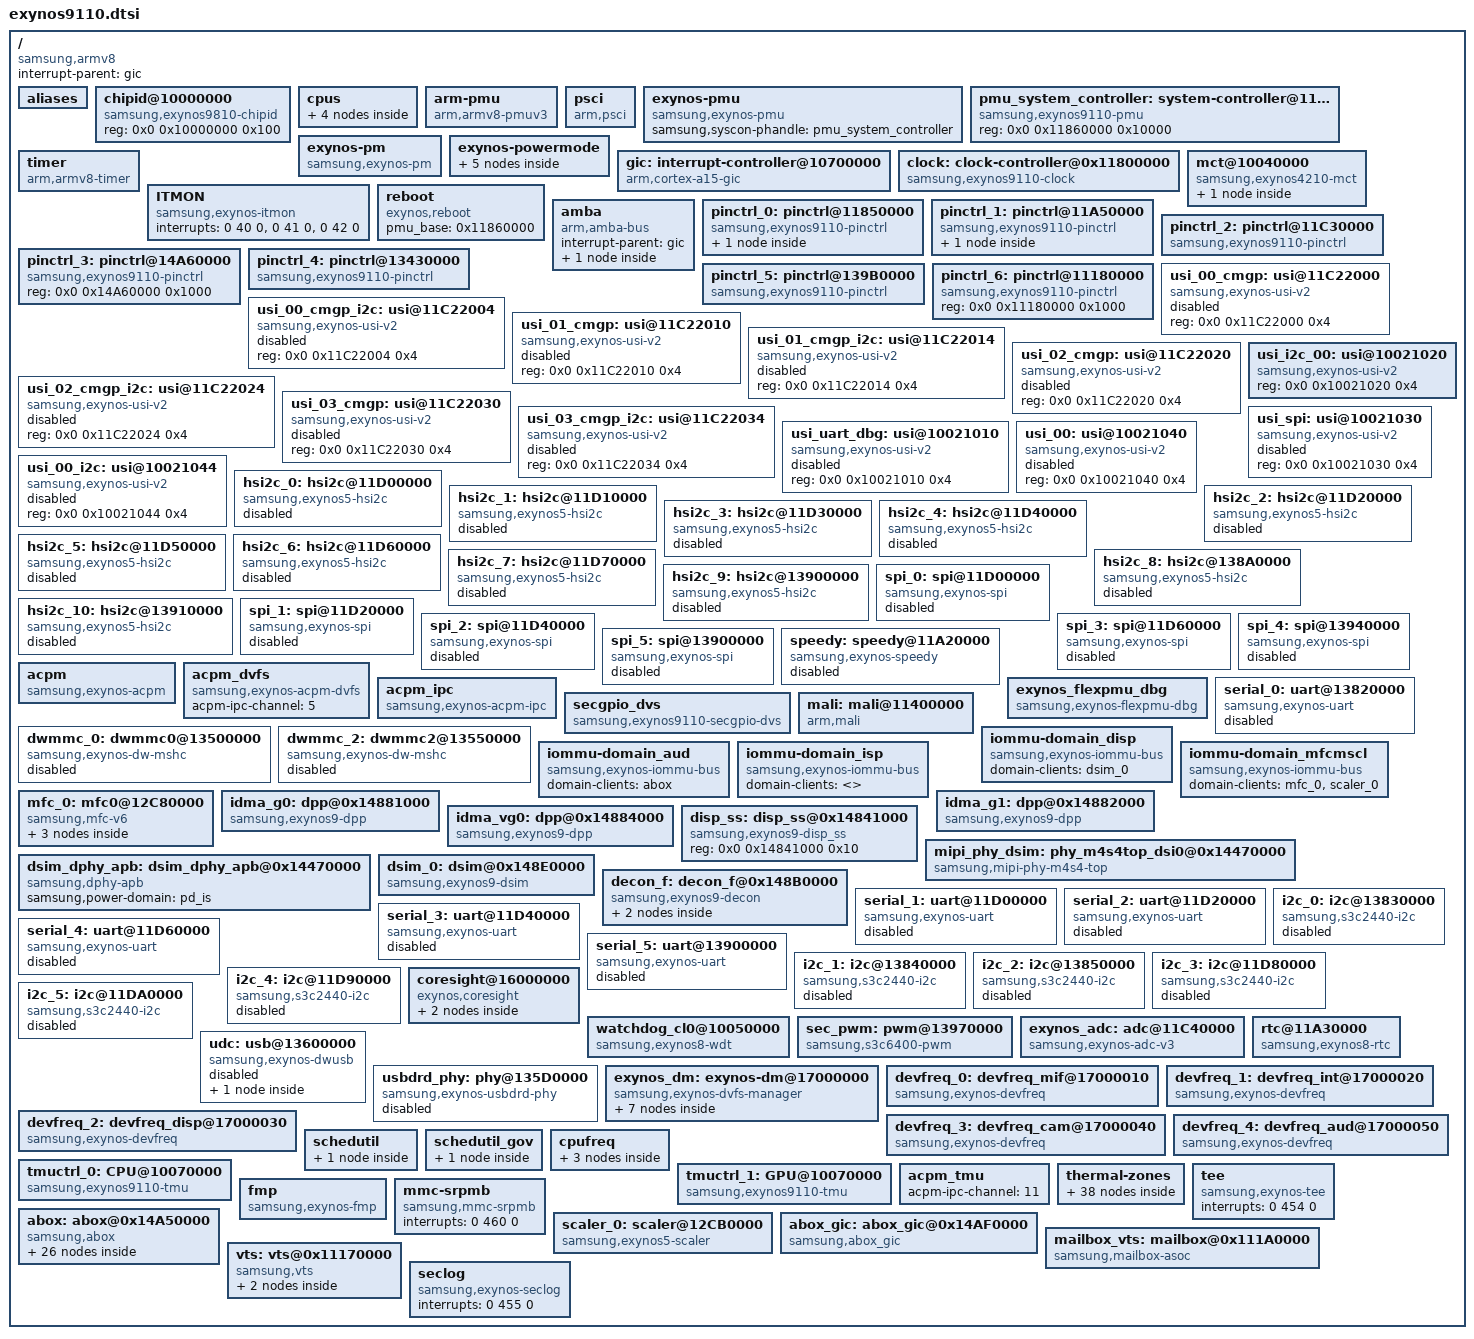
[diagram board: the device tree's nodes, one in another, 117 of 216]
/*
 * SAMSUNG EXYNOS9110 SoC device tree source
 *
 * Copyright (c) 2017 Samsung Electronics Co., Ltd.
 *		http://www.samsung.com
 *
 * SAMSUNG EXYNOS9110 SoC device nodes are listed in this file.
 * EXYNOS9110 based board files can include this file and provide
 * values for board specfic bindings.
 *
 * This program is free software; you can redistribute it and/or modify
 * it under the terms of the GNU General Public License version 2 as
 * published by the Free Software Foundation.
 */

#include <dt-bindings/clock/exynos9110.h>
#include <dt-bindings/soc/samsung/exynos9110.h>
#include <dt-bindings/interrupt-controller/arm-gic.h>
#include <dt-bindings/interrupt-controller/exynos9110.h>
#include "exynos9110-sysmmu.dtsi"
#include "exynos9110-pm-domains.dtsi"
#include "tgm-drm.dtsi"

/ {
	compatible = "samsung,armv8", "samsung,exynos9110";
	interrupt-parent = <&gic>;
	#address-cells = <2>;
	#size-cells = <1>;

	aliases {
		pinctrl0 = &pinctrl_0;
		pinctrl1 = &pinctrl_1;
		pinctrl2 = &pinctrl_2;
		pinctrl3 = &pinctrl_3;
		pinctrl4 = &pinctrl_4;
		pinctrl5 = &pinctrl_5;
		pinctrl6 = &pinctrl_6;
		mshc0 = &dwmmc_0;
		mshc2 = &dwmmc_2;
		dpp0 = &idma_g0;
		dpp1 = &idma_g1;
		dpp2 = &idma_vg0;
		dsim0 = &dsim_0;
		decon0 = &decon_f;
		usi0 = &usi_00_cmgp;
		usi1 = &usi_00_cmgp_i2c;
		usi2 = &usi_01_cmgp;
		usi3 = &usi_01_cmgp_i2c;
		usi4 = &usi_02_cmgp;
		usi5 = &usi_02_cmgp_i2c;
		usi6 = &usi_03_cmgp;
		usi7 = &usi_03_cmgp_i2c;
		usi8 = &usi_uart_dbg;
		usi9 = &usi_i2c_00;
		usi10 = &usi_spi;
		usi11 = &usi_00;
		usi12 = &usi_00_i2c;
		hsi2c0 = &hsi2c_0;
		hsi2c1 = &hsi2c_1;
		hsi2c2 = &hsi2c_2;
		hsi2c3 = &hsi2c_3;
		hsi2c4 = &hsi2c_4;
		hsi2c5 = &hsi2c_5;
		hsi2c6 = &hsi2c_6;
		hsi2c7 = &hsi2c_7;
		hsi2c8 = &hsi2c_8;
		hsi2c9 = &hsi2c_9;
		hsi2c10 = &hsi2c_10;
		spi0 = &spi_0;
		spi1 = &spi_1;
		spi2 = &spi_2;
		spi3 = &spi_3;
		spi4 = &spi_4;
		spi5 = &spi_5;
		uart0 = &serial_0;
		ecduart = &serial_0;
		uart1 = &serial_1;
		uart2 = &serial_2;
		uart3 = &serial_3;
		uart4 = &serial_4;
		uart5 = &serial_5;
		scaler0 = &scaler_0;
		mfc0 = &mfc_0;
	};

	chipid@10000000 {
		compatible = "samsung,exynos9810-chipid";
		reg = <0x0 0x10000000 0x100>;
	};

	cpus {
		#address-cells = <2>;
		#size-cells = <0>;

		cpu_l0:cpu@0 {
			device_type = "cpu";
			compatible = "arm,ananke", "arm,armv8";
			reg = <0x0 0x0>;
			enable-method = "psci";
			cpu-idle-states = <&BOOTCL_CPU_SLEEP>;
		};
		cpu_l1:cpu@1 {
			device_type = "cpu";
			compatible = "arm,ananke", "arm,armv8";
			reg = <0x0 0x1>;
			enable-method = "psci";
			cpu-idle-states = <&BOOTCL_CPU_SLEEP>;
		};
		idle-states {
			entry-method = "arm,psci";

			BOOTCL_CPU_SLEEP: bootcl-cpu-sleep {
				idle-state-name = "c2";
				compatible = "exynos,idle-state";
				arm,psci-suspend-param = <0x0010000>;
				entry-latency-us = <35>;
				exit-latency-us = <90>;
				min-residency-us = <750>;
				status = "okay";
			};
		};
	};

	arm-pmu {
		compatible = "arm,armv8-pmuv3";
		interrupts = <GIC_SPI 152 IRQ_TYPE_LEVEL_HIGH>,
			      <GIC_SPI 153 IRQ_TYPE_LEVEL_HIGH>;
		interrupt-affinity = <&cpu_l0>, <&cpu_l1>;
	};

	psci {
		compatible = "arm,psci";
		method = "smc";
		cpu_suspend = <0xC4000001>;
		cpu_off = <0x84000002>;
		cpu_on = <0xC4000003>;
	};

	exynos-pmu {
		compatible = "samsung,exynos-pmu";
		samsung,syscon-phandle = <&pmu_system_controller>;
	};

	pmu_system_controller: system-controller@11860000 {
		compatible = "samsung,exynos9110-pmu", "syscon";
		reg = <0x0 0x11860000 0x10000>;
	};

	exynos-pm {
		compatible = "samsung,exynos-pm";
		reg = <0x0 0x11850000 0x1000>,
		    <0x0 0x10701200 0x100>;
		reg-names = "gpio_alive_base",
				"gicd_ispendrn_base";
		num-eint = <13>;
		num-gic = <16>;
		suspend_mode_idx = <8>;		/* SYS_SLEEP */
		suspend_psci_idx = <133>;	/* PSCI_SYSTEM_SLEEP */
		cp_call_mode_idx = <10>;	/* SYS_SLEEP_AUD_ON */
		cp_call_psci_idx = <133>;	/* PSCI_SYSTEM_SLEEP */

		usbl2_suspend_available = <1>;	/* SYS_SLEEP_AUD_ON */
		usbl2_suspend_mode_idx = <12>;	/* SYS_SLEEP_AUD_ON */
		extra_wakeup_stat = <0x640>;
	};

	exynos-powermode {
		sicd_residency = <3000>;
		sicd_enabled = <1>;
		sicd_block_jig = <1>;

		idle-ip = "13970000.pwm",		/* [ 0] pwm		*/
			  "11c40000.adc",		/* [ 1] adc		*/
			  "11d00000.hsi2c",		/* [ 2] hsi2c_0		*/
			  "11d10000.hsi2c",		/* [ 3] hsi2c_1		*/
			  "11d20000.hsi2c",		/* [ 4] hsi2c_2		*/
			  "11d30000.hsi2c",		/* [ 5] hsi2c_3		*/
			  "11d40000.hsi2c",		/* [ 6] hsi2c_4		*/
			  "11d50000.hsi2c",		/* [ 7] hsi2c_5		*/
			  "11d60000.hsi2c",		/* [ 8] hsi2c_6		*/
			  "11d70000.hsi2c",		/* [ 9] hsi2c_7		*/
			  "138a0000.hsi2c",		/* [10] hsi2c_8		*/
			  "13900000.hsi2c",		/* [11] hsi2c_9		*/
			  "13910000.hsi2c",		/* [12] hsi2c_10	*/
			  "11d00000.spi",		/* [13] spi_0		*/
			  "11d20000.spi",		/* [14] spi_1		*/
			  "11d40000.spi",		/* [15] spi_2		*/
			  "11d60000.spi",		/* [16] spi_3		*/
			  "13940000.spi",		/* [17] spi_4		*/
			  "13900000.spi",		/* [18] spi_5		*/
			  "13500000.dwmmc0",		/* [19] dwmmc0		*/
			  "13550000.dwmmc2",		/* [20] dwmmc2		*/
			  "13600000.usb",		/* [21] usb		*/
			  "148e0000.dsim",		/* [22] dsim		*/
			  /* index for power-domain */
			  "pd-dispaud",			/* [23] pd-dispaud	*/
			  "pd-g3d",			/* [24] pd-g3d		*/
			  "pd-is",			/* [25] pd-is		*/
			  "pd-mfcmscl",			/* [26] pd-mfcmscl	*/
			  "pd-vts",			/* [27] pd-vts		*/
			  "bluetooth";			/* [28] bluetooth */

		fix-idle-ip = "acpm_dvfs";
		fix-idle-ip-index = <96>;

		idle_ip_mask {
			sicd: SYS_SICD {
				mode-index = <0>;
				ref-idle-ip = <0>,  <1>,  <2>,  <3>,  <4>,  <5>,  <6>,  <7>,  <8>,  <9>,
					     <10>, <11>, <12>, <13>, <14>, <15>, <16>, <17>, <18>, <19>,
					     <20>, <21>, <22>,       <24>,       <26>,       <28>, <96>;
			};
		};

		wakeup-masks {
			/*
			 * wakeup_mask configuration
			 *	        SICD          SICD_CPD      AFTR          STOP
			 *              LPD           LPA           ALPA          DSTOP
			 *              SLEEP         SLEEP_VTS_ON  SLEEP_AUD_ON  FAPO USB_L2
			 */
			wakeup-mask {
				mask = <0x400001E0>, <0x0>,        <0x0>,        <0x0>,
				       <0x0>,        <0x0>,        <0x0>,        <0x0>,
				       <0x500F7E7E>, <0x500F7E7E>, <0x500F7E7E>, <0x0>, <0xD00D7E7E>;
				reg-offset = <0x610>;
			};
			wakeup-mask3 {
				mask = <0x0>,	     <0x0>, 	   <0x0>, 	 <0x0>,
				       <0x0>,        <0x0>,        <0x0>,        <0x0>,
				       <0xFFFF00FF>, <0xFFFF00FF>, <0xFFFF00FF>, <0x0>, <0xFFFF00FF>;
				reg-offset = <0x618>;
			};
		};
	};

	gic:interrupt-controller@10700000 {
		compatible = "arm,cortex-a15-gic", "arm,cortex-a9-gic";
		#interrupt-cells = <3>;
		#address-cells = <0>;
		interrupt-controller;
		reg =	<0x0 0x10701000 0x1000>,
			<0x0 0x10702000 0x1000>,
			<0x0 0x10704000 0x2000>,
			<0x0 0x10706000 0x2000>;
		interrupts = <1 9 0xf04>;
	};

	timer {
		compatible = "arm,armv8-timer";
		interrupts = <GIC_PPI 13
				(GIC_CPU_MASK_SIMPLE(8) | IRQ_TYPE_LEVEL_LOW)>,
			     <GIC_PPI 14
				(GIC_CPU_MASK_SIMPLE(8) | IRQ_TYPE_LEVEL_LOW)>,
			     <GIC_PPI 11
				(GIC_CPU_MASK_SIMPLE(8) | IRQ_TYPE_LEVEL_LOW)>,
			     <GIC_PPI 10
				(GIC_CPU_MASK_SIMPLE(8) | IRQ_TYPE_LEVEL_LOW)>;
	        clock-frequency = <26000000>;
		use-clocksource-only;
		use-physical-timer;
	};

	clock: clock-controller@0x11800000 {
		compatible = "samsung,exynos9110-clock";
		reg = <0x0 0x11800000 0x8000>;
		acpm-ipc-channel = <0>;
		#clock-cells = <1>;
	};

	mct@10040000 {
		compatible = "samsung,exynos4210-mct";
		reg = <0x0 0x10040000 0x800>;
		interrupt-controller;
		#interrupt-cells = <1>;
		interrupt-parent = <&mct_map>;
		interrupts =	<0>, <1>, <2>, <3>,
				<4>, <5>, <6>, <7>,
				<8>, <9>, <10>, <11>;
		clocks = <&clock OSCCLK>, <&clock GATE_MCT>;
		clock-names = "fin_pll", "mct";
		use-clockevent-only;

		mct_map: mct-map {
			#interrupt-cells = <1>;
			#address-cells = <0>;
			#size-cells = <0>;
			interrupt-map = <0 &gic 0 233 0>,
					<1 &gic 0 234 0>,
					<2 &gic 0 235 0>,
					<3 &gic 0 236 0>,
					<4 &gic 0 237 0>,
					<5 &gic 0 238 0>,
					<6 &gic 0 239 0>,
					<7 &gic 0 240 0>,
					<8 &gic 0 241 0>,
					<9 &gic 0 242 0>,
					<10 &gic 0 243 0>,
					<11 &gic 0 244 0>;
		};
	};

	ITMON {
		compatible = "samsung,exynos-itmon";
		interrupts = <0 40 0>, /* DATA_CORE */
			     <0 41 0>, /* DATA_NRT */
			     <0 42 0>; /* PERI_CORE */
	};

	reboot {
		compatible = "exynos,reboot";
		pmu_base = <0x11860000>;
	};

	/* DMA */
	amba {
		#address-cells = <2>;
		#size-cells = <1>;
		compatible = "arm,amba-bus";
		interrupt-parent = <&gic>;
		ranges;

		pdma0: pdma0@10520000 {
			compatible = "arm,pl330", "arm,primecell";
			reg = <0x0 0x10520000 0x1000>;
			interrupts = <0 19 0>;
			clocks = <&clock GATE_PDMA_CORE>;
			clock-names = "apb_pclk";
			#dma-cells = <1>;
			#dma-channels = <4>;
			#dma-requests = <32>;
			#dma-multi-irq = <1>;
			dma-arwrapper = <0x10524400>,
					<0x10524420>,
					<0x10524440>,
					<0x10524460>;
			dma-awwrapper = <0x10524404>,
					<0x10524424>,
					<0x10524444>,
					<0x10524464>;
			dma-instwrapper = <0x10524480>;
			dma-mask-bit = <36>;
			coherent-mask-bit = <36>;
		};
	};

	/* ALIVE */
	pinctrl_0: pinctrl@11850000 {
		compatible = "samsung,exynos9110-pinctrl";
		reg = <0x0 0x11850000 0x1000>;
		interrupts = <0 74 0>, <0 75 0>, <0 76 0>, <0 77 0>,
				<0 78 0>, <0 79 0>, <0 80 0>, <0 81 0>,
				<0 82 0>, <0 83 0>, <0 84 0>, <0 85 0>,
				<0 86 0>, <0 87 0>;
		wakeup-interrupt-controller {
			compatible = "samsung,exynos7-wakeup-eint";
		};
	};

	/* CMGP_ALIVE */
	pinctrl_1: pinctrl@11A50000{
		compatible = "samsung,exynos9110-pinctrl";
		reg = <0x0 0x11A50000 0x1000>;
		interrupts = <0 122 0>, <0 123 0>, <0 124 0>, <0 125 0>,
				<0 142 0>, <0 143 0>, <0 144 0>, <0 145 0>,
				<0 146 0>, <0 147 0>;
		wakeup-interrupt-controller {
			compatible = "samsung,exynos7-wakeup-eint";
		};
	};

	/* CMGP */
	pinctrl_2: pinctrl@11C30000{
		compatible = "samsung,exynos9110-pinctrl";
		reg = <0x0 0x11C30000 0x1000>;
		interrupts = <0 126 0>, <0 127 0>, <0 128 0>, <0 129 0>,
				<0 130 0>, <0 131 0>, <0 132 0>, <0 133 0>,
				<0 134 0>, <0 135 0>, <0 136 0>, <0 137 0>,
				<0 138 0>, <0 139 0>, <0 140 0>, <0 141 0>;
	};

	/* DISPAUD */
	pinctrl_3: pinctrl@14A60000{
		compatible = "samsung,exynos9110-pinctrl";
		reg = <0x0 0x14A60000 0x1000>;
	};

	/* FSYS */
	pinctrl_4: pinctrl@13430000 {
		compatible = "samsung,exynos9110-pinctrl";
		reg = <0x0 0x13430000 0x1000>;
		interrupts = <0 180 0>;
	};

	/* PERI */
	pinctrl_5: pinctrl@139B0000 {
		compatible = "samsung,exynos9110-pinctrl";
		reg = <0x0 0x139B0000 0x1000>;
		interrupts = <0 256 0>;
	};

	/* VTS */
	pinctrl_6: pinctrl@11180000{
		compatible = "samsung,exynos9110-pinctrl";
		reg = <0x0 0x11180000 0x1000>;
	};

	/* USI_00_CMGP */
	usi_00_cmgp: usi@11C22000 {
		compatible = "samsung,exynos-usi-v2";
		reg = <0x0 0x11C22000 0x4>;
		/*	usi_mode_v2 = "i2c" or "spi" or "uart"	*/
		status = "disabled";
	};

	/* USI_00_CMGP_I2C */
	usi_00_cmgp_i2c: usi@11C22004 {
		compatible = "samsung,exynos-usi-v2";
		reg = <0x0 0x11C22004 0x4>;
		/*	usi_mode_v2 = "i2c" */
		status = "disabled";
	};

	/* USI_01_CMGP */
	usi_01_cmgp: usi@11C22010 {
		compatible = "samsung,exynos-usi-v2";
		reg = <0x0 0x11C22010 0x4>;
		/*	usi_mode_v2 = "i2c" or "spi" or "uart"	*/
		status = "disabled";
	};

	/* USI_01_CMGP_I2C */
	usi_01_cmgp_i2c: usi@11C22014 {
		compatible = "samsung,exynos-usi-v2";
		reg = <0x0 0x11C22014 0x4>;
		/*	usi_mode_v2 = "i2c" */
		status = "disabled";
	};

	/* USI_02_CMGP */
	usi_02_cmgp: usi@11C22020 {
		compatible = "samsung,exynos-usi-v2";
		reg = <0x0 0x11C22020 0x4>;
		/*	usi_mode_v2 = "i2c" or "spi" or "uart"	*/
		status = "disabled";
	};

	/* USI_02_CMGP_I2C */
	usi_02_cmgp_i2c: usi@11C22024 {
		compatible = "samsung,exynos-usi-v2";
		reg = <0x0 0x11C22024 0x4>;
		/*	usi_mode_v2 = "i2c" */
		status = "disabled";
	};

	/* USI_03_CMGP */
	usi_03_cmgp: usi@11C22030 {
		compatible = "samsung,exynos-usi-v2";
		reg = <0x0 0x11C22030 0x4>;
		/*	usi_mode_v2 = "i2c" or "spi" or "uart"	*/
		status = "disabled";
	};

	/* USI_03_CMGP_I2C */
	usi_03_cmgp_i2c: usi@11C22034 {
		compatible = "samsung,exynos-usi-v2";
		reg = <0x0 0x11C22034 0x4>;
		/*	usi_mode_v2 = "i2c" */
		status = "disabled";
	};

	/* USI_UART_DBG */
	usi_uart_dbg: usi@10021010 {
		compatible = "samsung,exynos-usi-v2";
		reg = <0x0 0x10021010 0x4>;
		/*	usi_mode_v2 = "i2c" */
		status = "disabled";
	};

	/* USI_I2C_00 */
	usi_i2c_00: usi@10021020 {
		compatible = "samsung,exynos-usi-v2";
		reg = <0x0 0x10021020 0x4>;
		/*	usi_mode_v2 = "i2c" */
		status = "okay";
	};

	/* USI_SPI */
	usi_spi: usi@10021030 {
		compatible = "samsung,exynos-usi-v2";
		reg = <0x0 0x10021030 0x4>;
		/*	usi_mode_v2 = "i2c" */
		status = "disabled";
	};

	/* USI_00 */
	usi_00: usi@10021040 {
		compatible = "samsung,exynos-usi-v2";
		reg = <0x0 0x10021040 0x4>;
		/*	usi_mode_v2 = "i2c" */
		status = "disabled";
	};

	/* USI_00_I2C */
	usi_00_i2c: usi@10021044 {
		compatible = "samsung,exynos-usi-v2";
		reg = <0x0 0x10021044 0x4>;
		/*	usi_mode_v2 = "i2c" */
		status = "disabled";
	};

	/* USI_00_CMGP */
	hsi2c_0: hsi2c@11D00000 {
		compatible = "samsung,exynos5-hsi2c";
		samsung,check-transdone-int;
		default-clk = <200000000>;
		reg = <0x0 0x11D00000 0x1000>;
		interrupts = <0 INTREQ_USI_CMGP_00 0>;
		#address-cells = <1>;
		#size-cells = <0>;
		pinctrl-names = "default";
		pinctrl-0 = <&hsi2c0_bus>;
		clocks = <&clock CMGP_USI0>, <&clock GATE_USI_CMGP0>;
		clock-names = "rate_hsi2c", "gate_hsi2c";
		samsung,scl-clk-stretching;
		samsung,usi-i2c-v2;
		gpio_scl= <&gpm0 0 0x1>;
		gpio_sda= <&gpm1 0 0x1>;
		status = "disabled";
	};

	/* USI_00_CMGP_I2C */
	hsi2c_1: hsi2c@11D10000 {
		compatible = "samsung,exynos5-hsi2c";
		samsung,check-transdone-int;
		default-clk = <200000000>;
		reg = <0x0 0x11D10000 0x1000>;
		interrupts = <0 INTREQ_USI_CMGP_00_I2C 0>;
		#address-cells = <1>;
		#size-cells = <0>;
		pinctrl-names = "default";
		pinctrl-0 = <&hsi2c1_bus>;
		clocks = <&clock CMGP_I2C0>, <&clock GATE_I2C_CMGP0>;
		clock-names = "rate_hsi2c", "gate_hsi2c";
		samsung,scl-clk-stretching;
		samsung,usi-i2c-v2;
		gpio_scl= <&gpm2 0 0x1>;
		gpio_sda= <&gpm3 0 0x1>;
		status = "disabled";
	};

	/* USI_01_CMGP */
	hsi2c_2: hsi2c@11D20000 {
		compatible = "samsung,exynos5-hsi2c";
		samsung,check-transdone-int;
		default-clk = <200000000>;
		reg = <0x0 0x11D20000 0x1000>;
		interrupts = <0 INTREQ_USI_CMGP_01 0>;
		#address-cells = <1>;
		#size-cells = <0>;
		pinctrl-names = "default";
		pinctrl-0 = <&hsi2c2_bus>;
		clocks = <&clock CMGP_USI1>, <&clock GATE_USI_CMGP1>;
		clock-names = "rate_hsi2c", "gate_hsi2c";
		samsung,scl-clk-stretching;
		samsung,usi-i2c-v2;
		gpio_scl= <&gpm4 0 0x1>;
		gpio_sda= <&gpm5 0 0x1>;
		status = "disabled";
	};

	/* USI_01_CMGP_I2C */
	hsi2c_3: hsi2c@11D30000 {
		compatible = "samsung,exynos5-hsi2c";
		samsung,check-transdone-int;
		default-clk = <200000000>;
		reg = <0x0 0x11D30000 0x1000>;
		interrupts = <0 INTREQ_USI_CMGP_01_I2C 0>;
		#address-cells = <1>;
		#size-cells = <0>;
		pinctrl-names = "default";
		pinctrl-0 = <&hsi2c3_bus>;
		clocks = <&clock CMGP_I2C1>, <&clock GATE_I2C_CMGP1>;
		clock-names = "rate_hsi2c", "gate_hsi2c";
		samsung,scl-clk-stretching;
		samsung,usi-i2c-v2;
		gpio_scl= <&gpm6 0 0x1>;
		gpio_sda= <&gpm7 0 0x1>;
		status = "disabled";
	};

	/* USI_02_CMGP */
	hsi2c_4: hsi2c@11D40000 {
		compatible = "samsung,exynos5-hsi2c";
		samsung,check-transdone-int;
		default-clk = <200000000>;
		reg = <0x0 0x11D40000 0x1000>;
		interrupts = <0 INTREQ_USI_CMGP_02 0>;
		#address-cells = <1>;
		#size-cells = <0>;
		pinctrl-names = "default";
		pinctrl-0 = <&hsi2c4_bus>;
		clocks = <&clock CMGP_USI2>, <&clock GATE_USI_CMGP2>;
		clock-names = "rate_hsi2c", "gate_hsi2c";
		samsung,scl-clk-stretching;
		samsung,usi-i2c-v2;
		gpio_scl= <&gpm8 0 0x1>;
		gpio_sda= <&gpm9 0 0x1>;
		status = "disabled";
	};

	/* USI_02_CMGP_I2C */
	hsi2c_5: hsi2c@11D50000 {
		compatible = "samsung,exynos5-hsi2c";
		samsung,check-transdone-int;
		default-clk = <200000000>;
		reg = <0x0 0x11D50000 0x1000>;
		interrupts = <0 INTREQ_USI_CMGP_02_I2C 0>;
		#address-cells = <1>;
		#size-cells = <0>;
		pinctrl-names = "default";
		pinctrl-0 = <&hsi2c5_bus>;
		clocks = <&clock CMGP_I2C2>, <&clock GATE_I2C_CMGP2>;
		clock-names = "rate_hsi2c", "gate_hsi2c";
		samsung,scl-clk-stretching;
		samsung,usi-i2c-v2;
		gpio_scl= <&gpm10 0 0x1>;
		gpio_sda= <&gpm11 0 0x1>;
		status = "disabled";
	};

	/* USI_03_CMGP */
	hsi2c_6: hsi2c@11D60000 {
		compatible = "samsung,exynos5-hsi2c";
		samsung,check-transdone-int;
		default-clk = <200000000>;
		reg = <0x0 0x11D60000 0x1000>;
		interrupts = <0 INTREQ_USI_CMGP_03 0>;
		#address-cells = <1>;
		#size-cells = <0>;
		pinctrl-names = "default";
		pinctrl-0 = <&hsi2c6_bus>;
		clocks = <&clock CMGP_USI3>, <&clock GATE_USI_CMGP3>;
		clock-names = "rate_hsi2c", "gate_hsi2c";
		samsung,scl-clk-stretching;
		samsung,usi-i2c-v2;
		gpio_scl= <&gpm12 0 0x1>;
		gpio_sda= <&gpm13 1 0x1>;
		status = "disabled";
	};

	/* USI_03_CMGP_I2C */
	hsi2c_7: hsi2c@11D70000 {
		compatible = "samsung,exynos5-hsi2c";
		samsung,check-transdone-int;
		default-clk = <200000000>;
		reg = <0x0 0x11D70000 0x1000>;
		interrupts = <0 INTREQ_USI_CMGP_03_I2C 0>;
		#address-cells = <1>;
		#size-cells = <0>;
		pinctrl-names = "default";
		pinctrl-0 = <&hsi2c7_bus>;
		clocks = <&clock CMGP_I2C3>, <&clock GATE_I2C_CMGP3>;
		clock-names = "rate_hsi2c", "gate_hsi2c";
		samsung,scl-clk-stretching;
		samsung,usi-i2c-v2;
		gpio_scl= <&gpm14 0 0x1>;
		gpio_sda= <&gpm15 1 0x1>;
		status = "disabled";
	};

	/* USI_I2C_00 */
	hsi2c_8: hsi2c@138A0000 {
		compatible = "samsung,exynos5-hsi2c";
		samsung,check-transdone-int;
		default-clk = <200000000>;
		reg = <0x0 0x138A0000 0x1000>;
		interrupts = <0 INTREQ_USI_I2C_00 0>;
		#address-cells = <1>;
		#size-cells = <0>;
		pinctrl-names = "default";
		pinctrl-0 = <&hsi2c8_bus>;
		clocks = <&clock PERI_HSI2C>, <&clock GATE_USI_I2C_0>;
		clock-names = "rate_hsi2c", "gate_hsi2c";
		samsung,scl-clk-stretching;
		samsung,usi-i2c-v2;
		gpio_scl= <&gpp3 0 0x1>;
		gpio_sda= <&gpp3 1 0x1>;
		status = "disabled";
	};

	/* USI_00 */
	hsi2c_9: hsi2c@13900000 {
		compatible = "samsung,exynos5-hsi2c";
		samsung,check-transdone-int;
		default-clk = <200000000>;
		reg = <0x0 0x13900000 0x1000>;
		interrupts = <0 INTREQ_USI_00 0>;
		#address-cells = <1>;
		#size-cells = <0>;
		pinctrl-names = "default";
		pinctrl-0 = <&hsi2c9_bus>;
		clocks = <&clock PERI_BUS>, <&clock GATE_I2C_0>;
		clock-names = "rate_hsi2c", "gate_hsi2c";
		samsung,scl-clk-stretching;
		samsung,usi-i2c-v2;
		gpio_scl= <&gpc0 0 0x1>;
		gpio_sda= <&gpc0 1 0x1>;
		status = "disabled";
	};

	/* USI_00_I2C */
	hsi2c_10: hsi2c@13910000 {
		compatible = "samsung,exynos5-hsi2c";
		samsung,check-transdone-int;
		default-clk = <200000000>;
		reg = <0x0 0x13910000 0x1000>;
		interrupts = <0 INTREQ_USI_00_I2C 0>;
		#address-cells = <1>;
		#size-cells = <0>;
		pinctrl-names = "default";
		pinctrl-0 = <&hsi2c10_bus>;
		clocks = <&clock PERI_BUS>, <&clock GATE_I2C_1>;
		clock-names = "rate_hsi2c", "gate_hsi2c";
		samsung,scl-clk-stretching;
		samsung,usi-i2c-v2;
		gpio_scl= <&gpc0 2 0x1>;
		gpio_sda= <&gpc0 3 0x1>;
		status = "disabled";
	};

	/* SPI USI_00_CMGP */
	spi_0: spi@11D00000 {
		compatible = "samsung,exynos-spi";
		reg = <0x0 0x11D00000 0x100>;
		samsung,spi-fifosize = <64>;
		interrupts = <0 INTREQ_USI_CMGP_00 0>;
/*
		dma-mode;
		dmas = <&pdma0 25 &pdma0 24>;
*/
		dma-names = "tx", "rx";
		swap-mode;
		#address-cells = <1>;
		#size-cells = <0>;
		clocks = <&clock GATE_USI_CMGP0>, <&clock CMGP_USI0>;
		clock-names = "spi", "spi_busclk0";
		pinctrl-names = "default";
		pinctrl-0 = <&spi0_bus>;
		status = "disabled";
	};

	/* SPI USI_01_CMGP */
	spi_1: spi@11D20000 {
		compatible = "samsung,exynos-spi";
		reg = <0x0 0x11D20000 0x100>;
		samsung,spi-fifosize = <64>;
		interrupts = <0 INTREQ_USI_CMGP_01 0>;
/*
		dma-mode;
		dmas = <&pdma0 25 &pdma0 24>;
*/
		dma-names = "tx", "rx";
		swap-mode;
		#address-cells = <1>;
		#size-cells = <0>;
		clocks = <&clock GATE_USI_CMGP1>, <&clock CMGP_USI1>;
		clock-names = "spi", "spi_busclk0";
		pinctrl-names = "default";
		pinctrl-0 = <&spi1_bus>;
		status = "disabled";
	};

	/* SPI USI_02_CMGP */
	spi_2: spi@11D40000 {
		compatible = "samsung,exynos-spi";
		reg = <0x0 0x11D40000 0x100>;
		samsung,spi-fifosize = <64>;
		interrupts = <0 INTREQ_USI_CMGP_02 0>;
/*
		dma-mode;
		dmas = <&pdma0 25 &pdma0 24>;
*/
		dma-names = "tx", "rx";
		swap-mode;
		#address-cells = <1>;
		#size-cells = <0>;
		clocks = <&clock GATE_USI_CMGP2>, <&clock CMGP_USI2>;
		clock-names = "spi", "spi_busclk0";
		pinctrl-names = "default";
		pinctrl-0 = <&spi2_bus>;
		status = "disabled";
	};

	/* SPI USI_03_CMGP */
	spi_3: spi@11D60000 {
		compatible = "samsung,exynos-spi";
		reg = <0x0 0x11D60000 0x100>;
		samsung,spi-fifosize = <64>;
		interrupts = <0 INTREQ_USI_CMGP_03 0>;
/*
		dma-mode;
		dmas = <&pdma0 25 &pdma0 24>;
*/
		dma-names = "tx", "rx";
		swap-mode;
		#address-cells = <1>;
		#size-cells = <0>;
		clocks = <&clock GATE_USI_CMGP3>, <&clock CMGP_USI3>;
		clock-names = "spi", "spi_busclk0";
		pinctrl-names = "default";
		pinctrl-0 = <&spi3_bus>;
		status = "disabled";
	};

	/* SPI USI_SPI */
	spi_4: spi@13940000 {
		compatible = "samsung,exynos-spi";
		reg = <0x0 0x13940000 0x100>;
		samsung,spi-fifosize = <64>;
		interrupts = <0 INTREQ_USI_SPI 0>;
/*
		dma-mode;
		dmas = <&pdma0 25 &pdma0 24>;
*/
		dma-names = "tx", "rx";
		swap-mode;
		#address-cells = <1>;
		#size-cells = <0>;
		clocks = <&clock GATE_USI_SPI>, <&clock PERI_SPI>;
		clock-names = "spi", "spi_busclk0";
		pinctrl-names = "default";
		pinctrl-0 = <&spi4_bus>;
		status = "disabled";
	};

	/* SPI USI_00 */
	spi_5: spi@13900000 {
		compatible = "samsung,exynos-spi";
		reg = <0x0 0x13900000 0x100>;
		samsung,spi-fifosize = <256>;
		interrupts = <0 INTREQ_USI_00 0>;
/*
		dma-mode;
		dmas = <&pdma0 25 &pdma0 24>;
*/
		dma-names = "tx", "rx";
		swap-mode;
		#address-cells = <1>;
		#size-cells = <0>;
		clocks = <&clock GATE_USI00_USI>, <&clock PERI_USI00_USI>;
		clock-names = "spi", "spi_busclk0";
		pinctrl-names = "default";
		pinctrl-0 = <&spi5_bus>;
		status = "disabled";
	};

	/* USI_UART DBG*/
	speedy: speedy@11A20000 {
		compatible = "samsung,exynos-speedy";
		reg = <0x0 0x11A20000 0x2000>;
		interrupts = <0 98 0>;
		#address-cells = <1>;
		#size-cells = <0>;
		pinctrl-names = "default";
		pinctrl-0 = <&speedy_bus>;
#if 0
		clocks = <&clock GATE_SPEEDY_BATCHER_WRAP_BATCHER_AP>;
		clock-names = "gate_speedy";
#endif
		status = "disabled";
	};

	acpm {
		compatible = "samsung,exynos-acpm";
		#address-cells = <2>;
		#size-cells = <1>;
		acpm-ipc-channel = <4>;
		fvmap_offset = <0x6000>;
		reg = <0x0 0x11830000 0x1000>;		/* TIMER_APM */
		reg-names = "timer_apm";
		peritimer-cnt = <0xFFFF>;
	};

	acpm_dvfs {
		compatible = "samsung,exynos-acpm-dvfs";
		acpm-ipc-channel = <5>;
	};

	acpm_ipc {
		compatible = "samsung,exynos-acpm-ipc";
		#address-cells = <2>;
		#size-cells = <1>;
		interrupts = <0 106 0>;	/* AP2APM MAILBOX SPI NUM*/
		reg = <0x0 0x11900000 0x1000>,		/* AP2APM MAILBOX */
			<0x0 0x2039000 0x30000>;	/* APM SRAM */
		initdata-base = <0x6F00>;
		num-timestamps = <32>;
		debug-log-level = <0>;
		logging-period = <500>;
		dump-base = <0x203C000>;
		dump-size = <0x17000>;			/* 92KB */
	};

	exynos_flexpmu_dbg {
		compatible = "samsung,exynos-flexpmu-dbg";
		#address-cells = <2>;
		#size-cells = <1>;
		data-base = <0x204A000>;
		data-size = <0x400>;
	};

	serial_0: uart@13820000 {
		compatible = "samsung,exynos-uart";
		samsung,separate-uart-clk;
		reg = <0x0 0x13820000 0x100>;
		samsung,fifo-size = <256>;
		interrupts = <0 INTREQ_USI_UART 0>;
		pinctrl-names = "default";
		pinctrl-0 = <&uart0_bus_single>; /* or _bus_dual */
		samsung,usi-serial-v2;
		clocks = <&clock GATE_USI_UART>, <&clock PERI_UART>;
		clock-names = "gate_pclk0", "gate_uart0";
		status = "disabled";
	};

	secgpio_dvs {
		compatible = "samsung,exynos9110-secgpio-dvs";
		status = "okay";
	};

	dwmmc_0: dwmmc0@13500000 {
		compatible = "samsung,exynos-dw-mshc";
		reg = <0x0 0x13500000 0x2000>,
			<0x0 0x13508000 0x200>;
		reg-names = "dw_mmc",
			"cmdq_mem";
		interrupts = <0 176 0>;
		#address-cells = <1>;
		#size-cells = <0>;
		clocks = <&clock FSYS_MMC_EMBD>, <&clock GATE_MMC_EMBD>;
		clock-names = "ciu", "ciu_gate";
		status = "disabled";
		fmp-id = <0>;
		smu-id = <0>;
	};

	dwmmc_2: dwmmc2@13550000 {
		compatible = "samsung,exynos-dw-mshc";
		reg = <0x0 0x13550000 0x2000>;
		reg-names = "dw_mmc";
		interrupts = <0 177 0>;
		#address-cells = <1>;
		#size-cells = <0>;
		clocks = <&clock FSYS_MMC_CARD>, <&clock GATE_MMC_CARD>;
		clock-names = "ciu", "ciu_gate";
		status = "disabled";
	 };

	mali: mali@11400000 {
		compatible = "arm,mali";
		reg = <0x0 0x11400000 0x5000>;
		interrupts = <0 70 0>, <0 71 0>, <0 69 0>;
		interrupt-names = "JOB", "MMU", "GPU";
		g3d_cmu_cal_id = <ACPM_DVFS_G3D>;
		samsung,power-domain = <&pd_g3d>;
		#cooling-cells = <2>; /* min followed by max */
	};

	iommu-domain_disp {
		compatible = "samsung,exynos-iommu-bus";
		#address-cells = <2>;
		#size-cells = <1>;
		ranges;

		domain-clients = <&dsim_0>;
	};
	iommu-domain_aud {
		compatible = "samsung,exynos-iommu-bus";
		#address-cells = <2>;
		#size-cells = <1>;
		ranges;

		domain-clients = <&abox>;
	};
	iommu-domain_isp {
		compatible = "samsung,exynos-iommu-bus";
		#address-cells = <2>;
		#size-cells = <1>;
		ranges;

		domain-clients = <>;
	};
	iommu-domain_mfcmscl {
		compatible = "samsung,exynos-iommu-bus";
		#address-cells = <2>;
		#size-cells = <1>;
		ranges;

		domain-clients = <&mfc_0>, <&scaler_0>;
	};

	mfc_0: mfc0@12C80000 {
		compatible = "samsung,mfc-v6";
		reg = <0x0 0x12C80000 0x10000>;
		interrupts = <0 206 0>;
		clock-names = "aclk_mfc";
		clocks = <&clock GATE_MFC>;
		samsung,power-domain = <&pd_mfcmscl>;
		iommus = <&sysmmu_mfcmscl>;
		status = "ok";
		ip_ver = <19>;
		clock_rate = <400000>;
		min_rate = <50000>;
		num_qos_steps = <2>;
		max_qos_steps = <2>;
		max_mb = <244800>;
		mfc_qos_table {
			mfc_qos_variant_0 {
				thrd_mb = <0>;
				freq_mfc = <267000>;
				freq_int = <200000>;
				freq_mif = <421000>;
				freq_cpu = <0>;
				freq_kfc = <0>;
				mo_value = <0>;
				time_fw = <322>;
			};
			mfc_qos_variant_1 {
				thrd_mb = <110727>;
				freq_mfc = <400000>;
				freq_int = <533000>;
				freq_mif = <1352000>;
				freq_cpu = <0>;
				freq_kfc = <0>;
				mo_value = <0>;
				time_fw = <156>;
			};
		};
	};

	idma_g0: dpp@0x14881000 {
		compatible = "samsung,exynos9-dpp";
		#pb-id-cells = <3>;
		/* DPP(fake), DPU_DMA, DPU_DMA_COMMON */
		reg = <0x0 0x14891000 0x1000>, <0x0 0x14881000 0x1000>, <0x0 0x14880000 0x110>;
		/* DPU_DMA IRQ, DPP IRQ */
		/* 54, 58 */
		interrupts = <0 54 0>, <0 58 0>;
/*		interrupts = <0 INTREQ__DPU_DMA_G0 0>, <0 INTREQ__DPU_DPP_G0 0>; */
	};

	idma_g1: dpp@0x14882000 {
		compatible = "samsung,exynos9-dpp";
		#pb-id-cells = <3>;
		/* DPP(fake), DPU_DMA */
		reg = <0x0 0x14892000 0x1000>, <0x0 0x14882000 0x1000>;
		/* DPU_DMA IRQ, DPP IRQ */
		/* 55, 59 */
		interrupts = <0 55 0>, <0 59 0>;
/*		interrupts = <0 INTREQ__DPU_DMA_G1 0>, <0 INTREQ__DPU_DPP_G1 0>; */
	};

	idma_vg0: dpp@0x14884000 {
		compatible = "samsung,exynos9-dpp";
		#pb-id-cells = <3>;
		/* DPP, DPU_DMA */
		reg = <0x0 0x14894000 0x1000>, <0x0 0x14884000 0x1000>;
		/* DPU_DMA IRQ, DPP IRQ */
		/* 57, 61 */
		interrupts = <0 57 0>, <0 61 0>;
/*		interrupts = <0 INTREQ__DPU_DMA_VG 0>, <0 INTREQ__DPU_DPP_VG 0>; */
	};

	disp_ss: disp_ss@0x14841000 {
		compatible = "samsung,exynos9-disp_ss";
		/* MIPI PHY CON : 0x14841008 */
		reg = <0x0 0x14841000 0x10>;
	};

	mipi_phy_dsim: phy_m4s4top_dsi0@0x14470000 {
		compatible = "samsung,mipi-phy-m4s4-top";
		samsung,pmu-syscon = <&pmu_system_controller>;
		/* MIPI_PHY_M4S4S2_TOP_CONTROL : PMU_BASE + 0x0730 */
		isolation = <0x0730>;
		/* PHY reset be controlled from DSIM */
		/* reg = <0x0 0x12821008 0x4>; */
		/* reset = <0 1>; */
		/* init = <4 5>; */ /* PHY reset control path bit of SYSREG */
		owner = <0>; /* 0: DSI,  1: CSI */
		#phy-cells = <1>;
	};

	dsim_dphy_apb: dsim_dphy_apb@0x14470000 {
		compatible = "samsung,dphy-apb";
		samsung,power-domain = <&pd_is>;
	};

	dsim_0: dsim@0x148E0000 {
		compatible = "samsung,exynos9-dsim";
		/* DSIM0, DPHY M4S4(APB) */
		reg = <0x0 0x148E0000 0x100>, <0x0 0x14470000 0x4000>;
		/* 53 */
		interrupts = <0 53 0>;
/*		interrupts = <0 INTREQ__DSIM0 0>; */
		iommus = <&sysmmu_dpu>;

		/* clock */
		clock-names = "aclk";
		clocks = <&clock GATE_DPU_S_DECON>;

		phys = <&mipi_phy_dsim 0>;
		phy-names = "dsim_dphy";

		/* power domain */
		samsung,power-domain = <&pd_dispaud>;
	};

	decon_f: decon_f@0x148B0000 {
		compatible = "samsung,exynos9-decon"; /* exynos9810 */
		#pb-id-cells = <4>;
		reg = <0x0 0x148B0000 0x10000>;

		/* interrupt num : FRAME_START, FRMAE_DONE, EXTRA, GPIO_PERIC1(EXT_INT_TE: GPC1[0]) */
		/* 50, 51, 52, 256 */
		interrupts = <0 50 0>,
			     <0 51 0>,
			     <0 52 0>,
			     <0 256 0>;
/*
		interrupts = <0 INTREQ__DPU_DECON0_FRAME_START 0>,
			     <0 INTREQ__DPU_DECON0_FRAME_DONE 0>,
			     <0 INTREQ__DPU_DECON0_EXTRA 0>,
			     <0 INTREQ__GPIO_PERIC 0>;
*/
		/* pinctrl */
		pinctrl-names = "hw_te_on", "hw_te_off";
		pinctrl-0 = <&decon_f_te_on &disp_rst_prev>;
		pinctrl-1 = <&decon_f_te_off &disp_rst_in>;

		max_win = <3>;
		default_win = <0>;
		default_idma = <0>;
		psr_mode = <2>;         /* 0: video mode, 1: DP command mode, 2: MIPI command mode */
		trig_mode = <0>;        /* 0: hw trigger, 1: sw trigger */
		dsi_mode = <0>;         /* 0: single dsi, 1: dual dsi */

		/* 0: DSI, 1: eDP, 2:HDMI, 3: WB */
		out_type = <0>;
		/* 0: DSI0, 1: DSI1, 2: DSI2 */
		out_idx = <0>;

		#address-cells = <2>;
		#size-cells = <1>;
		ranges;

		/* EINT for TE */
		gpios = <&gpc1 0 0xf>;
		/* sw te pending register */
		te_eint {
			/* NWEINT_GPC1_PEND */
			reg = <0x0 0x139B0A18 0x4>;
		};

		cam-stat {
			/* IS_STATUS */
			reg = <0x0 0x11864014 0x4>;
		};
	};

	/* USI_00_CMGP */
	serial_1: uart@11D00000 {
		compatible = "samsung,exynos-uart";
		samsung,separate-uart-clk;
		reg = <0x0 0x11D00000 0x100>;
		samsung,fifo-size = <64>;
		interrupts = <0 INTREQ_USI_CMGP_00 0>;
		pinctrl-names = "default";
		pinctrl-0 = <&uart1_bus_single>; /* or _bus_dual */
		samsung,usi-serial-v2;
		clocks = <&clock GATE_USI_CMGP0>, <&clock CMGP_USI0>;
		clock-names = "gate_pclk1", "gate_uart1";
		status = "disabled";
	};

	/* USI_01_CMGP */
	serial_2: uart@11D20000 {
		compatible = "samsung,exynos-uart";
		samsung,separate-uart-clk;
		reg = <0x0 0x11D20000 0x100>;
		samsung,fifo-size = <64>;
		interrupts = <0 INTREQ_USI_CMGP_01 0>;
		pinctrl-names = "default";
		pinctrl-0 = <&uart2_bus_single>; /* or _bus_dual */
		samsung,usi-serial-v2;
		clocks = <&clock GATE_USI_CMGP1>, <&clock CMGP_USI1>;
		clock-names = "gate_pclk2", "gate_uart2";
		status = "disabled";
	};

	/* USI_02_CMGP */
	serial_3: uart@11D40000 {
		compatible = "samsung,exynos-uart";
		samsung,separate-uart-clk;
		reg = <0x0 0x11D40000 0x100>;
		samsung,fifo-size = <64>;
		interrupts = <0 INTREQ_USI_CMGP_02 0>;
		pinctrl-names = "default";
		pinctrl-0 = <&uart3_bus_single>; /* or _bus_dual */
		samsung,usi-serial-v2;
		clocks = <&clock GATE_USI_CMGP2>, <&clock CMGP_USI2>;
		clock-names = "gate_pclk3", "gate_uart3";
		status = "disabled";
	};

	/* USI_03_CMGP */
	serial_4: uart@11D60000 {
		compatible = "samsung,exynos-uart";
		samsung,separate-uart-clk;
		reg = <0x0 0x11D60000 0x100>;
		samsung,fifo-size = <64>;
		interrupts = <0 INTREQ_USI_CMGP_03 0>;
		pinctrl-names = "default";
		pinctrl-0 = <&uart4_bus_single>; /* or _bus_dual */
		samsung,usi-serial-v2;
		clocks = <&clock GATE_USI_CMGP3>, <&clock CMGP_USI3>;
		clock-names = "gate_pclk4", "gate_uart4";
		status = "disabled";
	};

	/* USI_00 */
	serial_5: uart@13900000 {
		compatible = "samsung,exynos-uart";
		samsung,separate-uart-clk;
		reg = <0x0 0x13900000 0x100>;
		samsung,fifo-size = <256>;
		interrupts = <0 INTREQ_USI_00 0>;
		pinctrl-names = "default";
		pinctrl-0 = <&uart5_cts &uart5_rts &uart5_tx &uart5_rx>; /* Never change! This change fix UART suspend & resume problem */
		samsung,usi-serial-v2;
		clocks = <&clock GATE_USI00_USI>, <&clock PERI_USI00_USI>;
		clock-names = "gate_pclk5", "gate_uart5";
		status = "disabled";
	};

	/* I2C_0 */
	i2c_0: i2c@13830000 {
		compatible = "samsung,s3c2440-i2c";
		reg = <0x0 0x13830000 0x100>;
		interrupts = <0 INTREQ_I2C_0 0>;
		#address-cells = <1>;
		#size-cells = <0>;
		pinctrl-names = "default";
		pinctrl-0 = <&i2c0_bus>;
		clocks = <&clock PERI_BUS>, <&clock GATE_I2C_0>;
		clock-names = "rate_i2c", "gate_i2c";
		status = "disabled";
	};

	/* I2C_1 */
	i2c_1: i2c@13840000 {
		compatible = "samsung,s3c2440-i2c";
		reg = <0x0 0x13840000 0x100>;
		interrupts = <0 INTREQ_I2C_1 0>;
		#address-cells = <1>;
		#size-cells = <0>;
		pinctrl-names = "default";
		pinctrl-0 = <&i2c1_bus>;
		clocks = <&clock PERI_BUS>, <&clock GATE_I2C_1>;
		clock-names = "rate_i2c", "gate_i2c";
		status = "disabled";
	};

	/* I2C_2 */
	i2c_2: i2c@13850000 {
		compatible = "samsung,s3c2440-i2c";
		reg = <0x0 0x13850000 0x100>;
		interrupts = <0 INTREQ_I2C_2 0>;
		#address-cells = <1>;
		#size-cells = <0>;
		pinctrl-names = "default";
		pinctrl-0 = <&i2c2_bus>;
		clocks = <&clock PERI_BUS>, <&clock GATE_I2C_2>;
		clock-names = "rate_i2c", "gate_i2c";
		status = "disabled";
  		samsung,i2c-max-bus-freq = <400000>;
	};

	/* I2C_CMGP_4 */
	i2c_3: i2c@11D80000 {
		compatible = "samsung,s3c2440-i2c";
		reg = <0x0 0x11D80000 0x100>;
		interrupts = <0 INTREQ_I2C_CMGP_4 0>;
		#address-cells = <1>;
		#size-cells = <0>;
		pinctrl-names = "default";
		pinctrl-0 = <&i2c3_bus>;
		clocks = <&clock CMGP_BUS>, <&clock GATE_I2C_CMGP4>;
		clock-names = "rate_i2c", "gate_i2c";
		status = "disabled";
	};

	/* I2C_CMGP_5 */
	i2c_4: i2c@11D90000 {
		compatible = "samsung,s3c2440-i2c";
		reg = <0x0 0x11D90000 0x100>;
		interrupts = <0 INTREQ_I2C_CMGP_5 0>;
		#address-cells = <1>;
		#size-cells = <0>;
		pinctrl-names = "default";
		pinctrl-0 = <&i2c4_bus>;
		clocks = <&clock CMGP_BUS>, <&clock GATE_I2C_CMGP5>;
		clock-names = "rate_i2c", "gate_i2c";
		status = "disabled";
	};

	/* I2C_CMGP_6 */
	i2c_5: i2c@11DA0000 {
		compatible = "samsung,s3c2440-i2c";
		reg = <0x0 0x11DA0000 0x100>;
		interrupts = <0 INTREQ_I2C_CMGP_6 0>;
		#address-cells = <1>;
		#size-cells = <0>;
		pinctrl-names = "default";
		pinctrl-0 = <&i2c5_bus>;
		clocks = <&clock CMGP_BUS>, <&clock GATE_I2C_CMGP5>;
		clock-names = "rate_i2c", "gate_i2c";
		status = "disabled";
	};
	coresight@16000000 {
		compatible = "exynos,coresight";
		base = <0x16000000>;
		sj-offset = <0x6000>;

		cl0_cpu0@400000 {
			device_type = "cs";
			dbg-offset = <0x410000>;
		};
		cl0_cpu1@500000 {
			device_type = "cs";
			dbg-offset = <0x510000>;
		};
	};

	watchdog_cl0@10050000 {
		compatible = "samsung,exynos8-wdt";
		reg = <0x0 0x10050000 0x100>;
		interrupts = <0 INTREQ__WDT_CLUSTER0 0>;
		clocks = <&clock OSCCLK>, <&clock GATE_WDT_CLUSTER0>;
		clock-names = "rate_watchdog", "gate_watchdog";
		timeout-sec = <30>;
		samsung,syscon-phandle = <&pmu_system_controller>;
		index = <0>; /* if little cluster then index is 0 */
	};

	sec_pwm: pwm@13970000 {
		compatible = "samsung,s3c6400-pwm";
		reg = <0x0 0x13970000 0x1000>;
		samsung,pwm-outputs = <0>, <1>, <2>, <3>, <4>;
		#pwm-cells = <3>;
		clocks = <&clock GATE_PWM_MOTOR>, <&clock OSCCLK>;
		clock-names = "pwm_pclk", "pwm_sclk";
		status = "ok";
	};

	exynos_adc: adc@11C40000 {
		compatible = "samsung,exynos-adc-v3";
		reg = <0x0 0x11C40000 0x100>;
		interrupts = <0 INTREQ__ADC_CMGP_S0 0>;
		#io-channel-cells = <1>;
		io-channel-ranges;
		clocks = <&clock GATE_ADC_CMGP_S0>;
		clock-names = "gate_adcif";
	};

	rtc@11A30000 {
		compatible = "samsung,exynos8-rtc";
		reg = <0x0 0x11A30000 0x100>;
		interrupts = <0 INTREQ__RTC_ALARM_INT 0>, <0 INTREQ__RTC_TIC_INT_0 0>;
	};

	udc: usb@13600000 {
		compatible = "samsung,exynos-dwusb";
		clocks = <&clock GATE_USB20DRD_TOP_LINK>, <&clock GATE_USB20DRD_TOP_20CTRL>, <&clock GATE_USB20DRD_TOP_REFCLK>;
		clock-names = "hsdrd", "hsctrl", "refclk";
		reg = <0x0 0x13600000 0x10000>;
		#address-cells = <2>;
		#size-cells = <1>;
		ranges;
		status = "disabled";

		usbdrd_dwc3: dwc3 {
			compatible = "synopsys,dwc3";
			reg = <0x0 0x13600000 0x10000>;
			interrupts = <0 181 0>;
			//suspend_clk_freq = <66000000>;
			tx-fifo-resize = <0>;
			adj-sof-accuracy = <0>;
			is_not_vbus_pad = <1>;
			enable_sprs_transfer = <1>;
			qos_int_level = <100000 200000>;
			phys = <&usbdrd_phy 0>, <&usbdrd_phy 1>;
			phy-names = "usb2-phy", "usb3-phy";
			/* check susphy support */
			xhci_l2_support = <0>;
			/* support usb audio offloading: 1, if not: 0 */
			usb_audio_offloading = <0>;
			/* don't support USB L2 sleep */
			ldos = <0>;
			/*
			 * dis-u2-freeclk-exists-quirk, dis_u2_susphy_quirk are alternative.
			 * One of them should be selected
			 */
			snps,dis-u2-freeclk-exists-quirk;
			/* snps,dis_u2_susphy_quirk; */
		};
	};

	usbdrd_phy: phy@135D0000 {
		compatible = "samsung,exynos-usbdrd-phy";
		reg = <0x0 0x135D0000 0x200>;
		clocks = <&clock GATE_USB20DRD_TOP_LINK>, <&clock GATE_USB20DRD_TOP_20CTRL>, <&clock GATE_USB20DRD_TOP_REFCLK>,
			   <&clock OSCCLK>;
		clock-names = "hsdrd", "hsctrl", "refclk", "oscclk";
		samsung,pmu-syscon = <&pmu_system_controller>;
		pmu_mask = <0x1>;
		pmu_offset = <0x704>;
		//pmu_offset_dp = <0x66c>;

		/* USBDP combo phy version  - 0x200 */
		phy_version = <0x300>;
		/* if it doesn't need phy user mux, */
		/*  you should write "none" */
		/*  but refclk shouldn't be omitted */
		phyclk_mux = "none";
		phy_refclk = "oscclk";

		/* if Main phy has the other phy, it must be set to 1. jusf for usbphy_info */
		has_other_phy = <0>;
		/* if combo phy is used, it must be set to 1. usbphy_sub_info is enabled */
		has_combo_phy = <0>;
		sub_phy_version = <0x300>;

		/* ip type */
		/* USB3DRD = 0 */
		/*  USB3HOST = 1 */
		/*  USB2DRD = 2 */
		/*  USB2HOST = 3 */
		ip_type = <0x0>;

		/* for PHY CAL */
		/* choice only one item */
		phy_refsel_clockcore = <1>;
		phy_refsel_ext_osc = <0>;
		phy_refsel_xtal = <0>;
		phy_refsel_diff_pad = <0>;
		phy_refsel_diff_internal = <0>;
		phy_refsel_diff_single = <0>;

		/* true : 1 , false : 0 */
		use_io_for_ovc = <0>;
		common_block_disable = <1>;
		is_not_vbus_pad = <1>;
		used_phy_port = <0>;

		status = "disabled";

		#phy-cells = <1>;
		ranges;
	};

	exynos_dm: exynos-dm@17000000 {
		compatible = "samsung,exynos-dvfs-manager";
		reg = <0x0 0x17000000 0x0>;
		acpm-ipc-channel = <1>;
		cpufreq_cl0 {
			dm-index = <DM_CPU_CL0>;
			available = "true";
			cal_id = <ACPM_DVFS_CPUCL0>;
		};
		devfreq_mif {
			dm-index = <DM_MIF>;
			available = "true";
			policy_use = "true";
			cal_id = <ACPM_DVFS_MIF>;
		};
		devfreq_int {
			dm-index = <DM_INT>;
			available = "true";
			policy_use = "true";
			cal_id = <ACPM_DVFS_INT>;
		};
		devfreq_cam {
			dm-index = <DM_CAM>;
			available = "true";
			cal_id = <ACPM_DVFS_CAM>;
		};
		devfreq_disp {
			dm-index = <DM_DISP>;
			available = "true";
			cal_id = <ACPM_DVFS_DISP>;
		};
		devfreq_aud {
			dm-index = <DM_AUD>;
			available = "true";
			cal_id = <ACPM_DVFS_AUD>;
		};
		dvfs_gpu {
			dm-index = <DM_GPU>;
			available = "false";
			cal_id = <ACPM_DVFS_G3D>;
		};
	};

	devfreq_0: devfreq_mif@17000010 {
		compatible = "samsung,exynos-devfreq";
		reg = <0x0 0x17000010 0x0>;
		devfreq_type = "mif";
		devfreq_domain_name = "dvfs_mif";

		/* Delay time */
		use_delay_time = "true";
		delay_time_list = "20";

		freq_info = <1539000 421000 1014000 421000 1539000 1539000>;
		/* initial_freq, default_qos, suspend_freq, min_freq, max_freq reboot_freq */

		/* Booting value */
		boot_info = <40 1539000>;
		/* boot_qos_timeout, boot_freq */

		use_get_dev = "false";
		polling_ms = <0>;

		/* governor data */
		gov_name = "interactive";
		use_reg = "false";

		use_tmu = "true";
		use_cl_dvfs = "false";
		use_sw_clk = "false";
		dfs_id = <ACPM_DVFS_MIF>;
		acpm-ipc-channel = <1>;
		use_acpm = "true";
	};

	devfreq_1: devfreq_int@17000020 {
		compatible = "samsung,exynos-devfreq";
		reg = <0x0 0x17000020 0x0>;
		devfreq_type = "int";
		devfreq_domain_name = "dvfs_int";

		/* Delay time */
		use_delay_time = "false";

		freq_info = <533000 100000 50000 100000 533000 533000>;
		/* <initial_freq, default_qos, suspend_freq, min, max, reboot_freq> */

		/* Booting value */
		boot_info = <40 533000>;
		/* boot_qos_timeout, boot_freq */

		/* default_dev_profile */
		use_get_dev = "false";
		polling_ms = <0>;

		/* governor data */
		gov_name = "interactive";
		use_reg = "false";

		use_tmu = "true";
		use_cl_dvfs = "false";
		use_sw_clk = "false";
		dfs_id = <ACPM_DVFS_INT>;
		acpm-ipc-channel = <1>;
		use_acpm = "true";
	};

	devfreq_2: devfreq_disp@17000030 {
		compatible = "samsung,exynos-devfreq";
		reg = <0x0 0x17000040 0x0>;
		devfreq_type = "disp";
		devfreq_domain_name = "dvfs_disp";

		/* Delay time */
		use_delay_time = "false";

		freq_info = <178000 89000 890000 89000 178000 178000>;
		/* <initial_freq, default_qos, suspend_freq, min, max, reboot_freq> */

		/* Booting value */
		boot_info = <40 178000>;
		/* boot_qos_timeout, boot_freq */

		/* default dev profile */
		use_get_dev = "false";
		polling_ms = <0>;

		/* governor data */
		gov_name = "interactive";
		use_reg = "false";

		use_tmu = "true";
		use_cl_dvfs = "false";
		use_sw_clk = "false";
		dfs_id = <ACPM_DVFS_DISP>;
	};

	devfreq_3: devfreq_cam@17000040 {
		compatible = "samsung,exynos-devfreq";
		reg = <0x0 0x17000050 0x0>;
		devfreq_type = "cam";
		devfreq_domain_name = "dvfs_cam";

		/* Delay time */
		use_delay_time = "false";

		freq_info = <50000 50000 50000 50000 334000 50000>;
		/* <initial, default_qos, suspend_freq, min, max, reboot_freq> */

		/* Booting value */
		boot_info = <40 50000>;
		/* boot_qos_timeout, boot_freq */

		/* default dev profile */
		use_get_dev = "false";
		polling_ms = <0>;

		/* governor data */
		gov_name = "interactive";
		use_reg = "false";

		use_tmu = "true";
		use_cl_dvfs = "false";
		use_sw_clk = "false";
		dfs_id = <ACPM_DVFS_CAM>;
	};

	devfreq_4: devfreq_aud@17000050 {
		compatible = "samsung,exynos-devfreq";
		reg = <0x0 0x17000060 0x0>;
		devfreq_type = "aud";
		devfreq_domain_name = "dvfs_aud";

		/* Delay time */
		use_delay_time = "false";

		freq_info = <295000 295000 295000 295000 1180000 295000>;
		/* <initial, default_qos, suspend_freq, min, max, reboot_freq> */

		/* Booting value */
		boot_info = <40 295000>;
		/* boot_qos_timeout, boot_freq */

		/* default dev profile */
		use_get_dev = "false";
		polling_ms = <0>;

		/* governor data */
		gov_name = "interactive";
		use_reg = "false";

		use_tmu = "true";
		use_cl_dvfs = "false";
		use_sw_clk = "false";
		dfs_id = <ACPM_DVFS_AUD>;
	};

	schedutil {
		domain@0 {
			device_type = "freqvar-tune";
			shared-cpus = "0-1";

			up_rate_limit_table = < 5 >;
			down_rate_limit_table = < 5 >;
			upscale_ratio_table = < 80 >;
		};
	};

	schedutil_gov {
		schedutil_domain0: domain@0 {
			device_type = "schedutil-domain";
			shared-cpus = "0-1";

			enabled = <1>;		/* Enable */
			qos_min_class = <3>;
		};
	};

	cpufreq {
		cpufreq_domain0: domain@0 {
			device_type = "cpufreq-domain";
			sibling-cpus = "0-1";
			cal-id = <ACPM_DVFS_CPUCL0>;
			dm-type = <DM_CPU_CL0>;

			/* PM QoS Class ID*/
			pm_qos-min-class = <3>;
			pm_qos-max-class = <4>;

			min-freq = <449000>;
			#cooling-cells = <2>; /* min followed by max */

			dm-constraints {
				mif-perf {
					const-type = <CONSTRAINT_MIN>;
					dm-type = <DM_MIF>;
						/*  cpu     mif  */
					table = < 1144000 1539000
						  1099000 1539000
						  1014000 1352000
						   904000 1014000
						   839000 1014000
						   754000 1014000
						   676000  676000
						   598000  676000
						   449000  676000
						   299000      0
						   208000      0
						   >;
				};
			};

		 };
	};

	tmuctrl_0: CPU@10070000 {
		compatible = "samsung,exynos9110-tmu";
		reg = <0x0 0x10070000 0x700>;
		interrupts = <0 INTREQ__TMU 0>;
		tmu_name = "CPU";
		id = <0>;
		sensors = <1>;		/* 0x1 */
		sensing_mode = "max";
		#include "exynos9110-tmu-sensor-conf.dtsi"
	};

	tmuctrl_1: GPU@10070000 {
		compatible = "samsung,exynos9110-tmu";
		reg = <0x0 0x10070000 0x700>;
		interrupts = <0 INTREQ__TMU 0>;
		tmu_name = "GPU";
		id = <1>;
		sensors = <1>;		/* 0x1 */
		sensing_mode = "max";
		#include "exynos9110-tmu-sensor-conf.dtsi"
	};

	acpm_tmu {
		acpm-ipc-channel = <11>;
	};

	thermal-zones {
		cpu_thermal: CPU {
			zone_name  = "CPU_THERMAL";
			polling-delay-passive = <0>;
			polling-delay = <0>;
			thermal-sensors = <&tmuctrl_0>;

			trips {
				little_alert0: little-alert0 {
					temperature = <20000>; /* millicelsius */
					hysteresis = <5000>; /* millicelsius */
					type = "active";
				};
				little_alert1: little-alert1 {
					temperature = <76000>; /* millicelsius */
					hysteresis = <5000>; /* millicelsius */
					type = "active";
				};
				little_alert2: little-alert2 {
					temperature = <81000>; /* millicelsius */
					hysteresis = <5000>; /* millicelsius */
					type = "active";
				};
				little_alert3: little-alert3 {
					temperature = <86000>; /* millicelsius */
					hysteresis = <5000>; /* millicelsius */
					type = "active";
				};
				little_alert4: little-alert4 {
					temperature = <91000>; /* millicelsius */
					hysteresis = <5000>; /* millicelsius */
					type = "active";
				};
				little_alert5: little-alert5 {
					temperature = <96000>; /* millicelsius */
					hysteresis = <5000>; /* millicelsius */
					type = "active";
				};
				little_alert6: little-alert6 {
					temperature = <101000>; /* millicelsius */
					hysteresis = <5000>; /* millicelsius */
					type = "active";
				};
				little_hot: little-hot {
					temperature = <115000>; /* millicelsius */
					hysteresis = <5000>; /* millicelsius */
					type = "hot";
				};
			};

			cooling-maps {
				map0 {
				     trip = <&little_alert0>;
				     /* Corresponds to 1099MHz at freq_table */
				     cooling-device = <&cpufreq_domain0 0 0>;
				};
				map1 {
				     trip = <&little_alert1>;
				     /* Corresponds to 1014MHz at freq_table */
				     cooling-device = <&cpufreq_domain0 0 0>;
			       };
				map2 {
				     trip = <&little_alert2>;
				     /* Corresponds to 904MHz at freq_table */
				     cooling-device = <&cpufreq_domain0 0 0>;
				};
				map3 {
				     trip = <&little_alert3>;
				     /* Corresponds to 839MHz at freq_table */
				     cooling-device = <&cpufreq_domain0 0 0>;
				};
				map4 {
				     trip = <&little_alert4>;
				     /* Corresponds to 754MHz at freq_table */
				     cooling-device = <&cpufreq_domain0 0 0>;
				};
				map5 {
				     trip = <&little_alert5>;
				     /* Corresponds to 676MHz at freq_table */
				     cooling-device = <&cpufreq_domain0 0 0>;
			       };
				map6 {
				     trip = <&little_alert6>;
				     /* Corresponds to 598MHz at freq_table */
				     cooling-device = <&cpufreq_domain0 0 0>;
				};
				map7 {
				     trip = <&little_hot>;
				     /* Corresponds to 449MHz at freq_table */
				     cooling-device = <&cpufreq_domain0 0 0>;
				};
			};
		};

		gpu_thermal: GPU {
			zone_name  = "GPU_THERMAL";
			polling-delay-passive = <0>;
			polling-delay = <0>;
			thermal-sensors = <&tmuctrl_1>;

			trips {
				gpu_alert0: gpu-alert0 {
					temperature = <20000>; /* millicelsius */
					hysteresis = <5000>; /* millicelsius */
					type = "active";
				};
				gpu_alert1: gpu-alert1 {
					temperature = <76000>; /* millicelsius */
					hysteresis = <5000>; /* millicelsius */
					type = "active";
				};
				gpu_alert2: gpu-alert2 {
					temperature = <81000>; /* millicelsius */
					hysteresis = <5000>; /* millicelsius */
					type = "active";
				};
				gpu_alert3: gpu-alert3 {
					temperature = <86000>; /* millicelsius */
					hysteresis = <5000>; /* millicelsius */
					type = "active";
				};
				gpu_alert4: gpu-alert4 {
					temperature = <91000>; /* millicelsius */
					hysteresis = <5000>; /* millicelsius */
					type = "active";
				};
				gpu_alert5: gpu-alert5 {
					temperature = <96000>; /* millicelsius */
					hysteresis = <5000>; /* millicelsius */
					type = "active";
				};
				gpu_alert6: gpu-alert6 {
					temperature = <101000>; /* millicelsius */
					hysteresis = <5000>; /* millicelsius */
					type = "active";
				};
				gpu_hot: gpu-hot {
					temperature = <115000>; /* millicelsius */
					hysteresis = <5000>; /* millicelsius */
					type = "hot";
				};
			};

			cooling-maps {
				map0 {
				     trip = <&gpu_alert0>;
				     cooling-device = <&mali 0 0>;
				};
				map1 {
				     trip = <&gpu_alert1>;
				     cooling-device = <&mali 0 0>;
			       };
				map2 {
				     trip = <&gpu_alert2>;
				     cooling-device = <&mali 0 0>;
				};
				map3 {
				     trip = <&gpu_alert3>;
				     cooling-device = <&mali 0 0>;
				};
				map4 {
				     trip = <&gpu_alert4>;
				     cooling-device = <&mali 0 0>;
				};
				map5 {
				     trip = <&gpu_alert5>;
				     cooling-device = <&mali 0 0>;
			       };
				map6 {
				     trip = <&gpu_alert6>;
				     cooling-device = <&mali 0 0>;
				};
				map7 {
				     trip = <&gpu_hot>;
				     cooling-device = <&mali 0 0>;
				};
			};
		};
	};

	/* tbase */
	tee {
		compatible = "samsung,exynos-tee";
	        interrupts = <0 454 0>;
	};

	fmp: fmp {
		compatible = "samsung,exynos-fmp";
		exynos,block-type = "mmcblk0p";
		exynos,fips-block_offset = <5>;
	};

	mmc-srpmb {
		compatible = "samsung,mmc-srpmb";
		interrupts = <0 460 0>;
	};

	scaler_0: scaler@12CB0000 {
		compatible = "samsung,exynos5-scaler";
		reg = <0x0 0x12CB0000 0x1300>;
		interrupts = <0 205 0>;
		clocks = <&clock GATE_M2M>;
		clock-names = "gate";
		iommus = <&sysmmu_mfcmscl>;
		samsung,power-domain = <&pd_mfcmscl>;
	};

	abox_gic: abox_gic@0x14AF0000 {
		compatible = "samsung,abox_gic";
		reg = <0x0 0x14AF1000 0x1000>, <0x0 0x14AF2000 0x1004>;
		reg-names = "gicd", "gicc";
		interrupts = <0 INTREQ__ABOX_GIC400 0>;
	};

	abox: abox@0x14A50000 {
		compatible = "samsung,abox";
		reg = <0x0 0x14A50000 0x10000>, <0x0 0x14840000 0x3000>,
			<0x0 0x14B00000 0x31000>, <0x0 0x14AE0000 0x10000>;
		reg-names = "sfr", "sysreg", "sram", "timer";
		#address-cells = <2>;
		#size-cells = <1>;
		ranges;
		pinctrl-names = "default", "idle";
		pinctrl-0 = <&aud_codec_mclk>;
		pinctrl-1 = <&aud_codec_mclk_idle>;
		quirks = "try to asrc off", "off on suspend", "use lsi codec";
		#sound-dai-cells = <1>;
		samsung,power-domain = <&pd_dispaud>;
		ipc_tx_offset = <0x30000>;
		ipc_rx_offset = <0x30300>;
		ipc_tx_ack_offset = <0x302FC>;
		ipc_rx_ack_offset = <0x305FC>;
		abox_gic = <&abox_gic>;
		clocks = <&clock PLL_OUT_AUD>, <&clock GATE_ABOX_CPU>,
			<&clock DOUT_AUD_AUDIF>, <&clock DOUT_AUD_ACLK>;
		clock-names = "pll", "cpu", "audif", "bus";
		uaif_max_div = <512>;
		iommus = <&sysmmu_abox>;
		pm_qos_int = <0 0 0 0 0>;
		pm_qos_aud = <1180000 800000 590000 394000 0>;
		samsung,abox-bootargs = "init=ab0x vss=0";
		samsung,abox-bootargs-offset = <0x30E00>;

		abox_rdma_0: abox_rdma@0x14A51000 {
			compatible = "samsung,abox-rdma";
			reg = <0x0 0x14A51000 0x100>;
			id = <0>;
			type = "normal";
		};

		abox_rdma_1: abox_rdma@0x14A51100 {
			compatible = "samsung,abox-rdma";
			reg = <0x0 0x14A51100 0x100>;
			id = <1>;
			type = "normal";
		};

		abox_rdma_2: abox_rdma@0x14A51200 {
			compatible = "samsung,abox-rdma";
			reg = <0x0 0x14A51200 0x100>;
			id = <2>;
			type = "normal";
		};

		abox_rdma_3: abox_rdma@0x14A51300 {
			compatible = "samsung,abox-rdma";
			reg = <0x0 0x14A51300 0x100>;
			id = <3>;
			type = "sync";
		};

		abox_rdma_4: abox_rdma@0x14A51400 {
			compatible = "samsung,abox-rdma";
			reg = <0x0 0x14A51400 0x100>;
			id = <4>;
			type = "call";
		};

		abox_rdma_5: abox_rdma@0x14A51500 {
			compatible = "samsung,abox-rdma";
			reg = <0x0 0x14A51500 0x100>, <0x0 0x14B30600 0x70>;
			id = <5>;
			type = "compress";
		};

		abox_rdma_6: abox_rdma@0x14A51600 {
			compatible = "samsung,abox-rdma";
			reg = <0x0 0x14A51600 0x100>;
			id = <6>;
			type = "realtime";
		};

		abox_rdma_7: abox_rdma@0x14A51700 {
			compatible = "samsung,abox-rdma";
			reg = <0x0 0x14A51700 0x100>;
			id = <7>;
			type = "realtime";
		};

		abox_wdma_0: abox_wdma@0x14A52000 {
			compatible = "samsung,abox-wdma";
			reg = <0x0 0x14A52000 0x100>;
			id = <0>;
			type = "realtime";
		};

		abox_wdma_1: abox_wdma@0x14A52100 {
			compatible = "samsung,abox-wdma";
			reg = <0x0 0x14A52100 0x100>;
			id = <1>;
			type = "normal";
		};

		abox_wdma_2: abox_wdma@0x14A52200 {
			compatible = "samsung,abox-wdma";
			reg = <0x0 0x14A52200 0x100>;
			id = <2>;
			type = "call";
		};

		abox_wdma_3: abox_wdma@0x14A52300 {
			compatible = "samsung,abox-wdma";
			reg = <0x0 0x14A52300 0x100>;
			id = <3>;
			type = "realtime";
		};

		abox_wdma_4: abox_wdma@0x14A52400 {
			compatible = "samsung,abox-wdma";
			reg = <0x0 0x14A52400 0x100>;
			id = <4>;
			type = "vi-sensing";
		};

		abox_uaif_0: abox_uaif@0x14A50500 {
			compatible = "samsung,abox-uaif";
			reg = <0x0 0x14A50500 0x10>;
			id = <0>;
			clocks = <&clock DOUT_AUD_UAIF0>, <&clock GATE_ABOX_S_BCLK0>;
			clock-names = "bclk", "bclk_gate";
			pinctrl-names = "default", "sleep";
			pinctrl-0 = <&aud_i2s0_bus>;
			pinctrl-1 = <&aud_i2s0_idle>;
		};

		abox_uaif_1: abox_uaif@0x14A50510 {
			compatible = "samsung,abox-uaif";
			reg = <0x0 0x14A50510 0x10>;
			id = <1>;
			clocks = <&clock DOUT_AUD_UAIF1>, <&clock GATE_ABOX_S_BCLK1>;
			clock-names = "bclk", "bclk_gate";
			pinctrl-names = "default", "sleep";
			pinctrl-0 = <&aud_i2s1_bus>;
			pinctrl-1 = <&aud_i2s1_idle>;
		};

		abox_uaif_4: abox_uaif@0x14A50540 {
			compatible = "samsung,abox-uaif";
			reg = <0x0 0x14A50540 0x10>;
			id = <4>;
			/* UAIF4 is connected to UAIF0 as slave */
			clocks = <&clock DOUT_AUD_UAIF0>, <&clock GATE_ABOX_S_BCLK0>;
			clock-names = "bclk", "bclk_gate";
			#sound-dai-cells = <0>;
		};

		abox_effect: abox_effect@0x14B2E000 {
			status = "okay";
			compatible = "samsung,abox-effect";
			reg = <0x0 0x14B21000 0x1000>;
			reg-names = "reg";
			abox = <&abox>;
		};

		abox_debug: abox_debug@0 {
			compatible = "samsung,abox-debug";
			memory-region = <&abox_rmem>;
			reg = <0x0 0x0 0x0>;
		};

		ext_bin_0: ext_bin@0 {
			status = "okay";
			samsung,name = "APDV_AUDIO_SLSI.bin";
			samsung,area = <1>; /* 0:SRAM, 1:DRAM, 2:VSS */
			samsung,offset = <0x502000>;
		};
		ext_bin_1: ext_bin@1 {
			status = "okay";
			samsung,name = "APSV_AUDIO_SLSI.bin";
			samsung,area = <1>;
			samsung,offset = <0x50C000>;
		};
		ext_bin_2: ext_bin@2 {
			status = "disabled";
			samsung,name = "AP_AUDIO_SLSI.bin";
			samsung,area = <1>;
			samsung,offset = <0x510000>;
		};
		ext_bin_3: ext_bin@3 {
			status = "disabled";
			samsung,name = "SoundBoosterParam.bin";
			samsung,area = <1>;
			samsung,offset = <0x800000>;
		};
		ext_bin_4: ext_bin@4 {
			status = "disabled";
			samsung,name = "dummy.bin";
			samsung,area = <1>;
			samsung,offset = <0x800000>;
		};
		ext_bin_5: ext_bin@5 {
			status = "disabled";
			samsung,name = "dummy.bin";
			samsung,area = <1>;
			samsung,offset = <0x800000>;
		};
		ext_bin_6: ext_bin@6 {
			status = "disabled";
			samsung,name = "dummy.bin";
			samsung,area = <1>;
			samsung,offset = <0x800000>;
		};
		ext_bin_7: ext_bin@7 {
			status = "disabled";
			samsung,name = "dummy.bin";
			samsung,area = <1>;
			samsung,offset = <0x800000>;
		};
	};

	mailbox_vts: mailbox@0x111A0000 {
		compatible = "samsung,mailbox-asoc";
		reg = <0x0 0x111A0000 0x1000>;
		reg-names = "sfr";
		interrupts = <0 189 0>;
		interrupt-controller;
		#interrupt-cells = <1>;
	};

	vts: vts@0x11170000 {
		compatible = "samsung,vts";
		reg = <0x0 0x11110000 0x1000>, <0x0 0x11020000 0x10010>,
			<0x0 0x11170000 0x8>, <0x0 0x11200000 0xB0000>, <0x0 0x111F0000 0x50>;
		reg-names = "sfr", "baaw", "dmic", "sram", "gpr";
		#address-cells = <2>;
		#size-cells = <1>;
		ranges;
		pinctrl-names = "dmic_default", "amic_default", "idle";
		pinctrl-0 = <&dmic_bus_clk &dmic_pdm>;
		pinctrl-1 = <&amic_bus_clk &amic_pdm>;
		pinctrl-2 = <&mic_bus_clk_idle &dmic_pdm_idle &amic_pdm_idle>;
		samsung,power-domain = <&pd_vts>;
		clocks = <&clock GATE_VTS_CPU>, <&clock CLK_VTS_DMIC>,
			<&clock CLK_VTS_DMIC_IF>, <&clock CLK_VTS_DMIC_IF_DIV2>;
		clock-names = "rco", "dmic", "dmic_if", "dmic_sync";
		mailbox = <&mailbox_vts>;
		interrupt-parent = <&mailbox_vts>;
		interrupts = <0>, <1>, <2>, <3>, <4>, <5>, <6>, <7>, <8>, <9>;
		interrupt-names = "error", "boot_completed", "ipc_received", "voice_triggered",
				"trigger_period_elapsed", "record_period_elapsed",
				"debuglog_bufzero", "debuglog_bufone",
				"audio_dump", "log_dump";
		vts_dma0: vts_dma@0 {
			compatible = "samsung,vts-dma";
			vts = <&vts>;
			id = <0>;
			type = "vts-trigger";
		};

		vts_dma1: vts_dma@1 {
			compatible = "samsung,vts-dma";
			vts = <&vts>;
			id = <1>;
			type = "vts-record";
		};
	};

	/* Secure log */
	seclog {
		compatible = "samsung,exynos-seclog";
		interrupts = <0 455 0>;
	};
};
